# PIC32CM1216JH01048 device description
Architecture: CORTEX-M0PLUS; Family: PIC32CM; Series: PIC32CMJH01
Registers are 32-bit, read-write, reset 0x0 unless marked. A register's access mark holds for its fields unless they carry their own. Offsets are from the block's base; [hi:lo] are bit positions; {n}, {i} and the like mark numbered series; 'fields as' and 'values as' point back to an identical list.

## AC — Analog Comparators
Instances: AC 0x42004C00
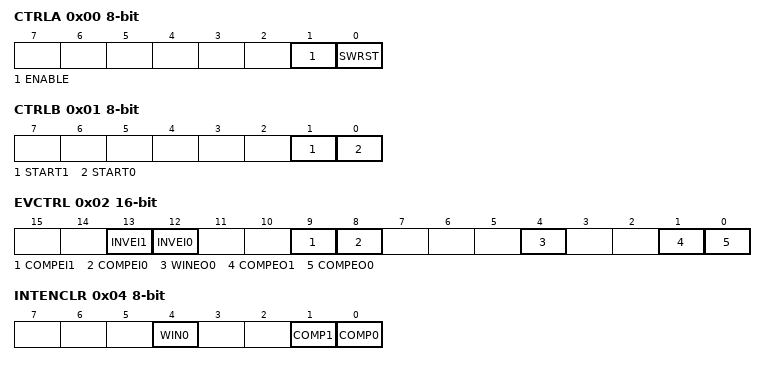
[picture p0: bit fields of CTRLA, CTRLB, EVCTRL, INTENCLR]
0x00 CTRLA 8-bit (WSYNC) — Control A
  [1] ENABLE
  [0] SWRST — Software Reset
0x01 CTRLB 8-bit — Control B
  [1] START1 — Comparator 1 Start Comparison
  [0] START0 — Comparator 0 Start Comparison
0x02 EVCTRL 16-bit — Event Control
  [13] INVEI1 — Comparator 1 Input Event Invert Enable
  [12] INVEI0 — Comparator 0 Input Event Invert Enable
  [9] COMPEI1 — Comparator 1 Event Input Enable
  [8] COMPEI0 — Comparator 0 Event Input Enable
  [4] WINEO0 — Window 0 Event Output Enable
  [1] COMPEO1 — Comparator 1 Event Output Enable
  [0] COMPEO0 — Comparator 0 Event Output Enable
0x04 INTENCLR 8-bit (atomic clear) — Interrupt Enable Clear
  [4] WIN0 — Window 0 Interrupt Enable
  [1] COMP1 — Comparator 1 Interrupt Enable
  [0] COMP0 — Comparator 0 Interrupt Enable
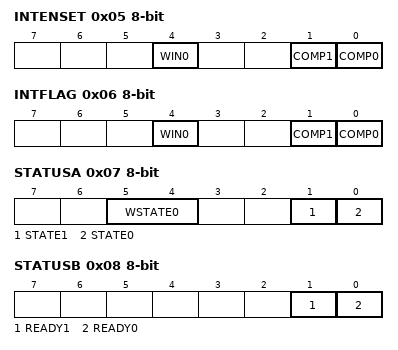
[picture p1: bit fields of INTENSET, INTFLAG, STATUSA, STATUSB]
0x05 INTENSET 8-bit (atomic set) — Interrupt Enable Set
  fields as INTENCLR
0x06 INTFLAG 8-bit (atomic clear) — Interrupt Flag Status and Clear
  [4] WIN0 — Window 0
  [1] COMP1 — Comparator 1
  [0] COMP0 — Comparator 0
0x07 STATUSA 8-bit ro
  [5:4] WSTATE0 — Window 0 Current State
    0=ABOVE (Signal is above window0); 1=INSIDE (Signal is inside window0); 2=BELOW (Signal is below window0)
  [1] STATE1 — Comparator 1 Current State
  [0] STATE0 — Comparator 0 Current State
0x08 STATUSB 8-bit ro
  [1] READY1 — Comparator 1 Ready
  [0] READY0 — Comparator 0 Ready
0x09 DBGCTRL 8-bit — Debug Control
  [0] DBGRUN — Debug Run
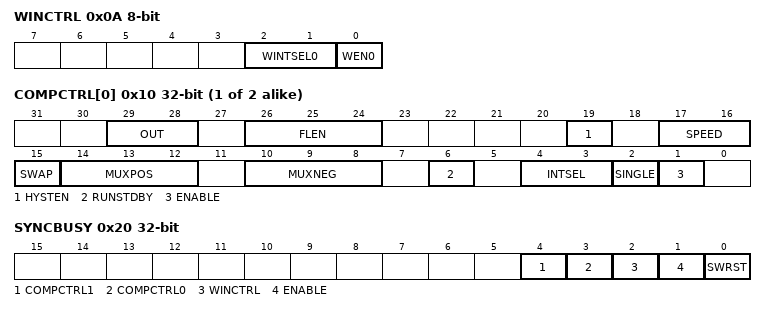
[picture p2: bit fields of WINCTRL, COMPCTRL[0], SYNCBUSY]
0x0A WINCTRL 8-bit (WSYNC) — Window Control
  [2:1] WINTSEL0 — Window 0 Interrupt Selection
    0=ABOVE (Interrupt on signal above window0); 1=INSIDE (Interrupt on signal inside window0); 2=BELOW (Interrupt on signal below window0); 3=OUTSIDE (Interrupt on signal outside window0)
  [0] WEN0 — Window 0 Mode Enable
{0xC+i} SCALER[{i}] (i=0..1) 8-bit — Scaler n
  [5:0] VALUE — Scaler Value
{0x10+4i} COMPCTRL[{i}] (i=0..1) (WSYNC) — Comparator Control n
  [29:28] OUT — Output
    0=OFF (The output of COMPn is not routed to the COMPn I/O port); 1=ASYNC (The asynchronous output of COMPn is routed to the COMPn I/O port); 2=SYNC (The synchronous output (including filtering) of COMPn is routed to the COMPn I/O port)
  [26:24] FLEN — Filter Length
    0=OFF (No filtering); 1=MAJ3 (3-bit majority function (2 of 3)); 2=MAJ5 (5-bit majority function (3 of 5))
  [19] HYSTEN — Hysteresis Enable
  [17:16] SPEED — Speed Selection
    0=LOW (Low speed); 3=HIGH (High speed)
  [15] SWAP — Swap Inputs and Invert
  [14:12] MUXPOS — Positive Input Mux Selection
    {v}=AIN{v} (I/O pin {v} for COMPCTRL0/1) (v=0..3); 4=VSCALE (VDD Scaler)
  [10:8] MUXNEG — Negative Input Mux Selection
    {v}=AIN{v} (I/O pin {v} for COMPCTRL0/1) (v=0..3); 4=GND (Ground); 5=VSCALE (VDD Scaler); 6=INTREF (Internal Voltage Reference)
  [6] RUNSTDBY — Run in Standby
  [4:3] INTSEL — Interrupt Selection
    0=TOGGLE (Interrupt on comparator output toggle); 1=RISING (Interrupt on comparator output rising); 2=FALLING (Interrupt on comparator output falling); 3=EOC (Interrupt on end of comparison (single-shot mode only))
  [2] SINGLE — Single-Shot Mode
  [1] ENABLE
0x20 SYNCBUSY ro — Synchronization Busy
  [4] COMPCTRL1 — COMPCTRL 1 Synchronization Busy
  [3] COMPCTRL0 — COMPCTRL 0 Synchronization Busy
  [2] WINCTRL — WINCTRL Synchronization Busy
  [1] ENABLE — Enable Synchronization Busy
  [0] SWRST — Software Reset Synchronization Busy

## CAN_RXBE — Rx Buffer Element
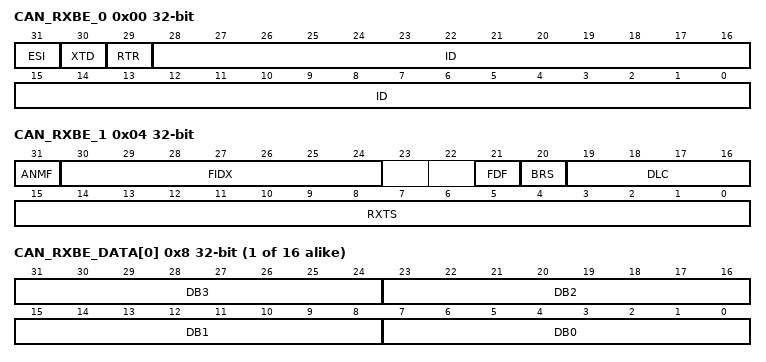
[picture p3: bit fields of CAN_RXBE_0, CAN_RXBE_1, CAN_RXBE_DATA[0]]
0x00 CAN_RXBE_0 — Rx Buffer Element 0
  [31] ESI — Error State Indicator
  [30] XTD — Extended Identifier
  [29] RTR — Remote Transmission Request
  [28:0] ID — Identifier
0x04 CAN_RXBE_1 — Rx Buffer Element 1
  [31] ANMF — Accepted Non-matching Frame
  [30:24] FIDX — Filter Index
  [21] FDF — FD Format
  [20] BRS — Bit Rate Switch
  [19:16] DLC — Data Length Code
  [15:0] RXTS — Rx Timestamp
{0x8+4i} CAN_RXBE_DATA[{i}] (i=0..15) — Rx Buffer Element Data
  [8n+7:8n] DB{n} (n=0..3) — Data Byte {n}
